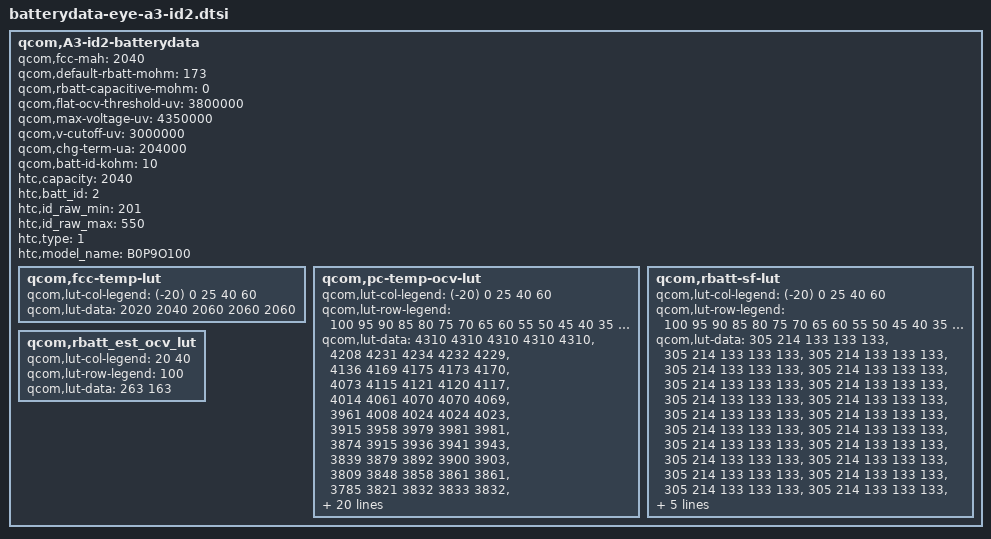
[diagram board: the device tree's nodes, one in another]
qcom,A3-id2-batterydata {
	qcom,fcc-mah = <2040>;
	qcom,default-rbatt-mohm = <173>;
	qcom,rbatt-capacitive-mohm = <0>;
	qcom,flat-ocv-threshold-uv = <3800000>;
	qcom,max-voltage-uv = <4350000>;
	qcom,v-cutoff-uv = <3000000>;
	qcom,chg-term-ua = <204000>;
	qcom,batt-id-kohm = <10>;
	htc,capacity = <2040>;
	htc,batt_id = <2>;
	htc,id_raw_min = <201>;
	htc,id_raw_max = <550>;
	htc,type = <1>;
	htc,model_name = "B0P9O100";

	qcom,fcc-temp-lut {
		qcom,lut-col-legend = <(-20) 0 25 40 60>;
		qcom,lut-data = <2020 2040 2060 2060 2060>;
	};

	qcom,pc-temp-ocv-lut {
		qcom,lut-col-legend = <(-20) 0 25 40 60>;
		qcom,lut-row-legend = <100 95 90 85 80 75 70 65 60 55 50 45 40 35 30 25 20 16 13 11 10 9 8 7 6 5 4 3 2 1 0>;
		qcom,lut-data = <4310 4310 4310 4310 4310>,
				<4208 4231 4234 4232 4229>,
				<4136 4169 4175 4173 4170>,
				<4073 4115 4121 4120 4117>,
				<4014 4061 4070 4070 4069>,
				<3961 4008 4024 4024 4023>,
				<3915 3958 3979 3981 3981>,
				<3874 3915 3936 3941 3943>,
				<3839 3879 3892 3900 3903>,
				<3809 3848 3858 3861 3861>,
				<3785 3821 3832 3833 3832>,
				<3764 3799 3811 3812 3811>,
				<3745 3780 3793 3795 3793>,
				<3727 3767 3778 3780 3778>,
				<3709 3755 3764 3762 3757>,
				<3690 3741 3746 3740 3728>,
				<3668 3722 3726 3720 3707>,
				<3646 3699 3705 3700 3688>,
				<3624 3676 3685 3681 3669>,
				<3608 3659 3671 3669 3659>,
				<3596 3651 3667 3666 3656>,
				<3581 3642 3662 3662 3652>,
				<3564 3632 3656 3656 3646>,
				<3544 3619 3645 3645 3632>,
				<3518 3600 3622 3619 3603>,
				<3485 3564 3580 3577 3561>,
				<3441 3505 3526 3523 3508>,
				<3380 3423 3457 3456 3442>,
				<3288 3313 3365 3368 3355>,
				<3154 3178 3232 3237 3226>,
				<3000 3000 3000 3000 3000>;
	};

	qcom,rbatt-sf-lut {
		qcom,lut-col-legend = <(-20) 0 25 40 60>;
		qcom,lut-row-legend = <100 95 90 85 80 75 70 65 60 55 50 45 40 35 30 25 20 16 13 11 10 9 8 7 6 5 4 3 2 1>;
		qcom,lut-data = <305 214 133 133 133>,
				<305 214 133 133 133>,
				<305 214 133 133 133>,
				<305 214 133 133 133>,
				<305 214 133 133 133>,
				<305 214 133 133 133>,
				<305 214 133 133 133>,
				<305 214 133 133 133>,
				<305 214 133 133 133>,
				<305 214 133 133 133>,
				<305 214 133 133 133>,
				<305 214 133 133 133>,
				<305 214 133 133 133>,
				<305 214 133 133 133>,
				<305 214 133 133 133>,
				<305 214 133 133 133>,
				<305 214 133 133 133>,
				<305 214 133 133 133>,
				<305 214 133 133 133>,
				<305 214 133 133 133>,
				<305 214 133 133 133>,
				<305 214 133 133 133>,
				<305 214 133 133 133>,
				<305 214 133 133 133>,
				<305 214 133 133 133>,
				<305 214 133 133 133>,
				<305 214 133 133 133>,
				<305 214 133 133 133>,
				<305 214 133 133 133>,
				<305 214 133 133 133>;
	};
	qcom,rbatt_est_ocv_lut {
		qcom,lut-col-legend = <20 40>;
		qcom,lut-row-legend = <100>;
		qcom,lut-data = <263 163>;
	};
};
